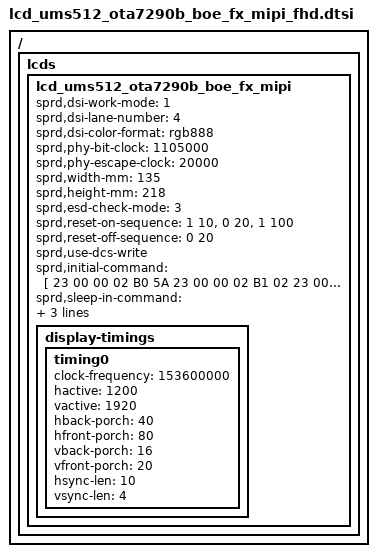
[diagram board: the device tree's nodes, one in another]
/ { lcds {
	lcd_ums512_ota7290b_boe_fx_mipi: lcd_ums512_ota7290b_boe_fx_mipi {

		sprd,dsi-work-mode = <1>; /* video burst mode*/
		sprd,dsi-lane-number = <4>;
		sprd,dsi-color-format = "rgb888";

		sprd,phy-bit-clock = <1105000>;  /* kbps */
		sprd,phy-escape-clock = <20000>;/* kHz */

		sprd,width-mm = <135>;
		sprd,height-mm = <218>;

		sprd,esd-check-mode = <3>;

		sprd,reset-on-sequence = <1 10>, <0 20>, <1 100>;
		sprd,reset-off-sequence = <0 20>;

		sprd,use-dcs-write;

		sprd,initial-command = [
			23 00 00 02 B0 5A
			23 00 00 02 B1 02
			23 00 00 02 0A 01
			13 78 00 01 11
			13 64 00 01 29
			];

		sprd,sleep-in-command = [
			13 0A 00 01 28
			13 78 00 01 10
			];
		sprd,sleep-out-command = [
			13 78 00 01 11
			13 64 00 01 29
			];

		display-timings {
			timing0 {
				clock-frequency = <153600000>;
				hactive = <1200>;
				vactive = <1920>;
				hback-porch = <40>;
				hfront-porch = <80>;
				vback-porch = <16>;
				vfront-porch = <20>;
				hsync-len = <10>;
				vsync-len = <4>;
			};
		};
	};
};};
